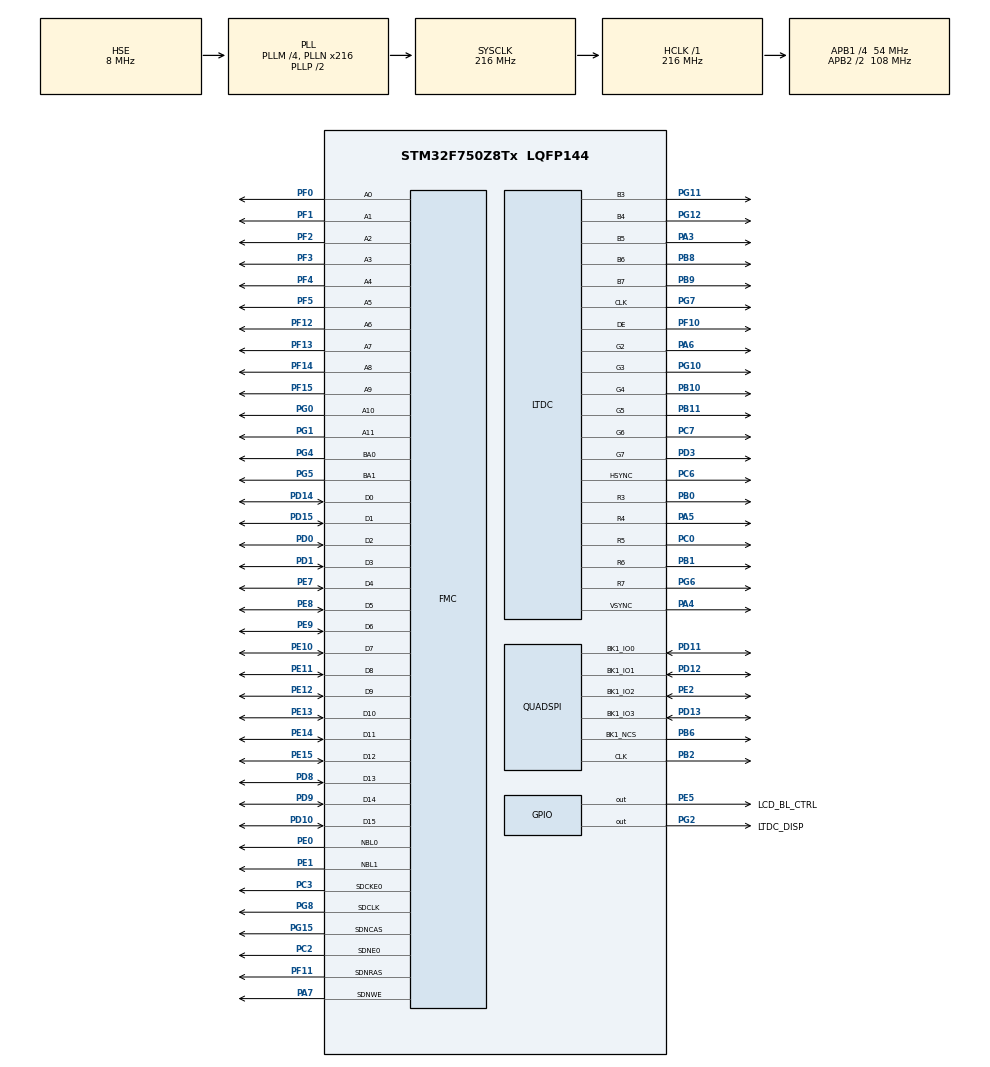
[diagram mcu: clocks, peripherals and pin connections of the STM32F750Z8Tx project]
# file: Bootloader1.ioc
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CORTEX_M7.CPU_DCache=Disabled
CORTEX_M7.CPU_ICache=Disabled
CORTEX_M7.MPU_Control=__NULL
DMA2D.ColorMode=DMA2D_OUTPUT_RGB565
Dma.MEMTOMEM.1.Direction=DMA_MEMORY_TO_MEMORY
Dma.MEMTOMEM.1.FIFOMode=DMA_FIFOMODE_ENABLE
Dma.MEMTOMEM.1.FIFOThreshold=DMA_FIFO_THRESHOLD_FULL
Dma.MEMTOMEM.1.Instance=DMA2_Stream0
Dma.MEMTOMEM.1.MemBurst=DMA_MBURST_SINGLE
Dma.MEMTOMEM.1.MemDataAlignment=DMA_MDATAALIGN_BYTE
Dma.MEMTOMEM.1.MemInc=DMA_MINC_ENABLE
Dma.MEMTOMEM.1.Mode=DMA_NORMAL
Dma.MEMTOMEM.1.PeriphBurst=DMA_PBURST_SINGLE
Dma.MEMTOMEM.1.PeriphDataAlignment=DMA_PDATAALIGN_BYTE
Dma.MEMTOMEM.1.PeriphInc=DMA_PINC_ENABLE
Dma.MEMTOMEM.1.Priority=DMA_PRIORITY_LOW
Dma.QUADSPI.0.Direction=DMA_PERIPH_TO_MEMORY
Dma.QUADSPI.0.FIFOMode=DMA_FIFOMODE_DISABLE
Dma.QUADSPI.0.Instance=DMA2_Stream7
Dma.QUADSPI.0.MemDataAlignment=DMA_MDATAALIGN_BYTE
Dma.QUADSPI.0.MemInc=DMA_MINC_ENABLE
Dma.QUADSPI.0.Mode=DMA_NORMAL
Dma.QUADSPI.0.PeriphDataAlignment=DMA_PDATAALIGN_BYTE
Dma.QUADSPI.0.PeriphInc=DMA_PINC_DISABLE
Dma.QUADSPI.0.Priority=DMA_PRIORITY_LOW
Dma.Request0=QUADSPI
Dma.Request1=MEMTOMEM
FMC.CASLatency1=FMC_SDRAM_CAS_LATENCY_3
FMC.ExitSelfRefreshDelay1=7
FMC.LoadToActiveDelay1=2
FMC.RCDDelay1=2
FMC.RPDelay1=2
FMC.ReadBurst1=FMC_SDRAM_RBURST_ENABLE
FMC.RowCycleDelay1=7
FMC.SDClockPeriod1=FMC_SDRAM_CLOCK_PERIOD_2
FMC.SelfRefreshTime1=4
FMC.WriteRecoveryTime1=3
LTDC.ActiveH=480
LTDC.ActiveW=800
LTDC.Alpha_L0=255
LTDC.FBStartAdress_L0=0xC0500000
LTDC.HBP=8
LTDC.HFP=8
LTDC.HSync=4
LTDC.ImageHeight_L0=480
LTDC.ImageWidth_L0=800
LTDC.Layers=0
LTDC.PCPolarity=LTDC_PCPOLARITY_IPC
LTDC.PixelFormat_L0=LTDC_PIXEL_FORMAT_RGB565
LTDC.VBP=8
LTDC.VFP=8
LTDC.VSync=4
LTDC.WindowX1_L0=800
LTDC.WindowY1_L0=480
Mcu.Family=STM32F7
Mcu.Name=STM32F750Z8Tx
Mcu.Package=LQFP144
NVIC.DMA2_Stream7_IRQn=true\:0\:0\:false\:false\:true\:false\:true
NVIC.FMC_IRQn=true\:0\:0\:false\:false\:true\:true\:true
NVIC.LTDC_ER_IRQn=true\:0\:0\:false\:false\:true\:true\:true
NVIC.LTDC_IRQn=true\:0\:0\:false\:false\:true\:true\:true
NVIC.PriorityGroup=NVIC_PRIORITYGROUP_4
NVIC.TIM2_IRQn=true\:0\:0\:false\:false\:true\:true\:true
NVIC.TIM5_IRQn=true\:0\:0\:false\:false\:true\:false\:true
NVIC.TimeBase=TIM5_IRQn
NVIC.TimeBaseIP=TIM5
PA1.Signal=LTDC_R2
PA13.Mode=Serial_Wire
PA13.Signal=SYS_JTMS-SWDIO
PA14.Mode=Serial_Wire
PA14.Signal=SYS_JTCK-SWCLK
PA3.Mode=RGB565
PA3.Signal=LTDC_B5
PA4.Mode=RGB565
PA4.Signal=LTDC_VSYNC
PA5.Mode=RGB565
PA5.Signal=LTDC_R4
PA6.Mode=RGB565
PA6.Signal=LTDC_G2
PA7.Signal=FMC_SDNWE
PB0.Mode=RGB565
PB0.Signal=LTDC_R3
PB1.Mode=RGB565
PB1.Signal=LTDC_R6
PB10.Mode=RGB565
PB10.Signal=LTDC_G4
PB11.Mode=RGB565
PB11.Signal=LTDC_G5
PB2.Mode=Single Bank 1
PB2.Signal=QUADSPI_CLK
PB3.Signal=SYS_JTDO-SWO
PB6.Mode=Single Bank 1
PB6.Signal=QUADSPI_BK1_NCS
PB8.Mode=RGB565
PB8.Signal=LTDC_B6
PB9.Mode=RGB565
PB9.Signal=LTDC_B7
PC0.Mode=RGB565
PC0.Signal=LTDC_R5
PC2.Mode=SdramChipSelect1_1
PC2.Signal=FMC_SDNE0
PC3.Mode=SdramChipSelect1_1
PC3.Signal=FMC_SDCKE0
PC6.Mode=RGB565
PC6.Signal=LTDC_HSYNC
PC7.Mode=RGB565
PC7.Signal=LTDC_G6
PD0.Signal=FMC_D2_DA2
PD1.Signal=FMC_D3_DA3
PD10.Signal=FMC_D15_DA15
PD11.Mode=Single Bank 1
PD11.Signal=QUADSPI_BK1_IO0
PD12.Mode=Single Bank 1
PD12.Signal=QUADSPI_BK1_IO1
PD13.Mode=Single Bank 1
PD13.Signal=QUADSPI_BK1_IO3
PD14.Signal=FMC_D0_DA0
PD15.Signal=FMC_D1_DA1
PD3.Mode=RGB565
PD3.Signal=LTDC_G7
PD6.Signal=LTDC_B2
PD8.Signal=FMC_D13_DA13
PD9.Signal=FMC_D14_DA14
PE0.Signal=FMC_NBL0
PE1.Signal=FMC_NBL1
PE10.Signal=FMC_D7_DA7
PE11.Signal=FMC_D8_DA8
PE12.Signal=FMC_D9_DA9
PE13.Signal=FMC_D10_DA10
PE14.Signal=FMC_D11_DA11
PE15.Signal=FMC_D12_DA12
PE2.Mode=Single Bank 1
PE2.Signal=QUADSPI_BK1_IO2
PE5.GPIO_Label=LCD_BL_CTRL
PE5.Signal=GPIO_Output
PE7.Signal=FMC_D4_DA4
PE8.Signal=FMC_D5_DA5
PE9.Signal=FMC_D6_DA6
PF0.Signal=FMC_A0
PF1.Signal=FMC_A1
PF10.Mode=RGB565
PF10.Signal=LTDC_DE
PF11.Signal=FMC_SDNRAS
PF12.Signal=FMC_A6
PF13.Signal=FMC_A7
PF14.Signal=FMC_A8
PF15.Signal=FMC_A9
PF2.Signal=FMC_A2
PF3.Signal=FMC_A3
PF4.Signal=FMC_A4
PF5.Signal=FMC_A5
PG0.Signal=FMC_A10
PG1.Signal=FMC_A11
PG10.Mode=RGB565
PG10.Signal=LTDC_G3
PG11.Mode=RGB565
PG11.Signal=LTDC_B3
PG12.Mode=RGB565
PG12.Signal=LTDC_B4
PG15.Signal=FMC_SDNCAS
PG2.GPIO_Label=LTDC_DISP
PG2.Signal=GPIO_Output
PG4.Signal=FMC_A14_BA0
PG5.Signal=FMC_A15_BA1
PG6.Mode=RGB565
PG6.Signal=LTDC_R7
PG7.Mode=RGB565
PG7.Signal=LTDC_CLK
PG8.Signal=FMC_SDCLK
PH0/OSC_IN.Mode=HSE-External-Oscillator
PH0/OSC_IN.Signal=RCC_OSC_IN
PH1/OSC_OUT.Mode=HSE-External-Oscillator
PH1/OSC_OUT.Signal=RCC_OSC_OUT
ProjectManager.HeapSize=0x200
ProjectManager.StackSize=0x400
ProjectManager.TargetToolchain=STM32CubeIDE
QUADSPI.ChipSelectHighTime=QSPI_CS_HIGH_TIME_8_CYCLE
QUADSPI.ClockPrescaler=2
QUADSPI.FifoThreshold=4
QUADSPI.FlashSize=16
QUADSPI.SampleShifting=QSPI_SAMPLE_SHIFTING_NONE
RCC.AHBFreq_Value=216000000
RCC.APB1CLKDivider=RCC_HCLK_DIV4
RCC.APB1Freq_Value=54000000
RCC.APB1TimFreq_Value=108000000
RCC.APB2CLKDivider=RCC_HCLK_DIV2
RCC.APB2Freq_Value=108000000
RCC.APB2TimFreq_Value=216000000
RCC.CortexFreq_Value=216000000
RCC.HCLKFreq_Value=216000000
RCC.HSE_VALUE=8000000
RCC.HSI_VALUE=16000000
RCC.LSE_VALUE=32768
RCC.PLLM=4
RCC.PLLN=216
RCC.PLLSAIN=69
RCC.PLLSAIR=3
RCC.PLLSourceVirtual=RCC_PLLSOURCE_HSE
RCC.SYSCLKFreq_VALUE=216000000
RCC.SYSCLKSource=RCC_SYSCLKSOURCE_PLLCLK
RCC.USBFreq_Value=216000000
RCC.VCOOutputFreq_Value=432000000
SH.FMC_A0.0=FMC_A0,12b-sda1
SH.FMC_A1.0=FMC_A1,12b-sda1
SH.FMC_A10.0=FMC_A10,12b-sda1
SH.FMC_A11.0=FMC_A11,12b-sda1
SH.FMC_A14_BA0.0=FMC_BA0,FourSdramBanks1
SH.FMC_A15_BA1.0=FMC_BA1,FourSdramBanks1
SH.FMC_A2.0=FMC_A2,12b-sda1
SH.FMC_A3.0=FMC_A3,12b-sda1
SH.FMC_A4.0=FMC_A4,12b-sda1
SH.FMC_A5.0=FMC_A5,12b-sda1
SH.FMC_A6.0=FMC_A6,12b-sda1
SH.FMC_A7.0=FMC_A7,12b-sda1
SH.FMC_A8.0=FMC_A8,12b-sda1
SH.FMC_A9.0=FMC_A9,12b-sda1
SH.FMC_D0_DA0.0=FMC_D0,sd-16b-d1
SH.FMC_D10_DA10.0=FMC_D10,sd-16b-d1
SH.FMC_D11_DA11.0=FMC_D11,sd-16b-d1
SH.FMC_D12_DA12.0=FMC_D12,sd-16b-d1
SH.FMC_D13_DA13.0=FMC_D13,sd-16b-d1
SH.FMC_D14_DA14.0=FMC_D14,sd-16b-d1
SH.FMC_D15_DA15.0=FMC_D15,sd-16b-d1
SH.FMC_D1_DA1.0=FMC_D1,sd-16b-d1
SH.FMC_D2_DA2.0=FMC_D2,sd-16b-d1
SH.FMC_D3_DA3.0=FMC_D3,sd-16b-d1
SH.FMC_D4_DA4.0=FMC_D4,sd-16b-d1
SH.FMC_D5_DA5.0=FMC_D5,sd-16b-d1
SH.FMC_D6_DA6.0=FMC_D6,sd-16b-d1
SH.FMC_D7_DA7.0=FMC_D7,sd-16b-d1
SH.FMC_D8_DA8.0=FMC_D8,sd-16b-d1
SH.FMC_D9_DA9.0=FMC_D9,sd-16b-d1
SH.FMC_NBL0.0=FMC_NBL0,Sd2ByteEnable1
SH.FMC_NBL1.0=FMC_NBL1,Sd2ByteEnable1
SH.FMC_SDCLK.0=FMC_SDCLK,12b-sda1
SH.FMC_SDNCAS.0=FMC_SDNCAS,12b-sda1
SH.FMC_SDNRAS.0=FMC_SDNRAS,12b-sda1
SH.FMC_SDNWE.0=FMC_SDNWE,12b-sda1
TIM2.Period=1000-1
TIM2.Prescaler=540-1
TIM7.Period=0
VP_DMA2D_VS_DMA2D.Mode=DMA2D_Activate
VP_SYS_VS_tim5.Mode=TIM5
VP_TIM2_VS_ClockSourceINT.Mode=Internal
VP_TIM7_VS_ClockSourceINT.Mode=Enable_Timer
board=custom

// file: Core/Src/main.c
/* USER CODE BEGIN Header */
/**
 ******************************************************************************
 * @file           : main.c
 * @brief          : Main program body
 ******************************************************************************
 * @attention
 *
 * <h2><center>&copy; Copyright (c) 2020 STMicroelectronics.
 * All rights reserved.</center></h2>
 *
 * This software component is licensed by ST under Ultimate Liberty license
 * SLA0044, the "License"; You may not use this file except in compliance with
 * the License. You may obtain a copy of the License at:
 *                             www.st.com/SLA0044
 *
 ******************************************************************************
 */
/* USER CODE END Header */
#include "main.h"

/* USER CODE BEGIN Includes */
#include "memory.h"
#include "qspi.h"
#include "crc.h"
#include <stdbool.h>
#include <string.h>

/* USER CODE END Includes */

/* USER CODE BEGIN PTD */

typedef struct FileHeader {
  uint32_t crcFile;
  uint32_t fileType;
  uint32_t fileOffset;
  uint32_t dummy3;
  uint32_t dummy4;
  uint32_t dummy5;
  uint32_t fileSize;
  uint32_t crcHeader;
} FileHeader_t;

typedef void (*pFunction)(void);

/* USER CODE END PTD */

/* USER CODE BEGIN PD */
//
#define ADDR_SDRAM_BASE         ((uint32_t)0xC0000000)
#define ADDR_SDRAM_APPLICATION  ((uint32_t)0xC0020000)
#define ADDR_DISPLAY_MEM    ((uint32_t)0xC0500000)

#define APPLICATION_FILEHEAD      0x90020200
#define APPLICATION_BASE          0x90020000

#define COLORBLACK 0x00000000
#define COLORWHITE 0xFFFFFFFF
#define COLORRED   0x78007800
#define COLORBLUE  0x001F001F

/* USER CODE END PD */

DMA2D_HandleTypeDef hdma2d;

LTDC_HandleTypeDef hltdc;

QSPI_HandleTypeDef hqspi;
DMA_HandleTypeDef hdma_quadspi;

TIM_HandleTypeDef htim2;
TIM_HandleTypeDef htim7;

DMA_HandleTypeDef hdma_memtomem_dma2_stream0;
SDRAM_HandleTypeDef hsdram1;

/* USER CODE BEGIN PV */
extern TIM_HandleTypeDef htim5;

uint8_t color = 0x1F;

/* USER CODE END PV */

void SystemClock_Config(void);
static void MX_GPIO_Init(void);
static void MX_DMA_Init(void);
static void MX_QUADSPI_Init(void);
static void MX_DMA2D_Init(void);
static void MX_LTDC_Init(void);
static void MX_FMC_Init(void);
static void MX_TIM7_Init(void);
static void MX_TIM2_Init(void);
/* USER CODE BEGIN PFP */
void MX_SDRAM_InitEx(void);

#ifdef __GNUC__
/* With GCC, small printf (option LD Linker->Libraries->Small printf
   set to 'Yes') calls __io_putchar() */
#define PUTCHAR_PROTOTYPE int __io_putchar(int ch)
#else
#define PUTCHAR_PROTOTYPE int fputc(int ch, FILE *f)
#endif /* __GNUC__ */

/* USER CODE END PFP */

/* USER CODE BEGIN 0 */

void HW_VerifySDRAM(void)
{
  volatile uint32_t *pBuf = (uint32_t*) 0xc0000000;

  static uint32_t failCnt = 0;
  uint32_t cnt = 8 * 1024 * 1024 / 4;

  for (uint32_t i = 0; i < cnt; i++)
    *(pBuf++) = i;

  pBuf = (uint32_t*) 0xc0000000;

  for (uint32_t i = 0; i < cnt; i++)
    if (*(pBuf++) != i)
      failCnt++;
}

void HW_VerifyLCD(void)
{
  uint16_t posX = 0;
  uint16_t posY = 0;

  volatile uint16_t *pFrameBuf = (uint16_t*) ADDR_DISPLAY_MEM;

  for (posY = 0; posY < 480; posY++)
  {
	  *pFrameBuf = color;
    for (posX = 0; posX < 800; posX++)
    {
    	*pFrameBuf = color;
      pFrameBuf++;
    }
  }
}
/**
  * @brief  Retargets the C library printf function to the USART.
  * @param  None
  * @retval None
  */
#if 0
PUTCHAR_PROTOTYPE
{
  /* Place your implementation of fputc here */
  /* e.g. write a character to the EVAL_COM1 and Loop until the end of transmission */
  HAL_UART_Transmit(&huart5, (uint8_t *)&ch, 1, 0xFFFF);

  return ch;
}
#endif

void LCD_Power_On_Sequence()
{
	HAL_GPIO_WritePin(LTDC_DISP_GPIO_Port, LTDC_DISP_Pin, GPIO_PIN_RESET);

	HAL_Delay( 100 );

	HAL_GPIO_WritePin(LTDC_DISP_GPIO_Port, LTDC_DISP_Pin, GPIO_PIN_SET);

	HAL_Delay( 25 );
}

uint8_t CheckApplicationChecksum()
{
  uint32_t crc;

  FileHeader_t *head = ( FileHeader_t* )( APPLICATION_FILEHEAD );

  crc = crc32( 0xDEADBEEF, ( uint8_t* )head, sizeof( FileHeader_t ) - 4 );

  if( crc != head->crcHeader )
    return false;

  uint32_t len = ( APPLICATION_FILEHEAD - APPLICATION_BASE );
  crc = crc32( 0xDEADBEEF, ( uint8_t* )APPLICATION_BASE, len );

  len = head->fileSize - ( APPLICATION_FILEHEAD - APPLICATION_BASE ) - sizeof( FileHeader_t );
  crc = crc32( crc, ( uint8_t* )( APPLICATION_FILEHEAD + sizeof( FileHeader_t ) ), len );

  if( crc != head->crcFile )
    return false;

  return true;
}

static void startApplication()
{
  HAL_LTDC_DeInit(&hltdc);
  HAL_TIM_Base_DeInit(&htim5);
  HAL_TIM_Base_DeInit(&htim7);

  pFunction JumpToRunCode;

  SysTick->CTRL = 0;
  uint32_t appAddress = SDRAM_DEVICE_ADDR_APPLICATION;
  /* Initialize user application's Stack Pointer & Jump to user application */
  JumpToRunCode = (pFunction) (*(__IO uint32_t*) (appAddress + 4));
  __set_MSP(*(__IO uint32_t*) appAddress);

  JumpToRunCode();
}

/* USER CODE END 0 */

int main(void)
{
  /* USER CODE BEGIN 1 */
  MPU_Region_InitTypeDef MPU_InitStruct;

  /* Configure unused area of QSPI region as strongly ordered.
   * This is *important* to avoid unintentional fetches from illegal
   * addresses due to cache/speculation which would halt the MCU.
   */
  HAL_MPU_Disable();

  /* Enable D-cache on SDRAM (Write-through) */
  MPU_InitStruct.Enable = MPU_REGION_ENABLE;
  MPU_InitStruct.BaseAddress = ADDR_SDRAM_BASE;
  MPU_InitStruct.Size = MPU_REGION_SIZE_8MB;
  MPU_InitStruct.AccessPermission = MPU_REGION_FULL_ACCESS;
  MPU_InitStruct.IsBufferable = MPU_ACCESS_NOT_BUFFERABLE;
  MPU_InitStruct.IsCacheable = MPU_ACCESS_CACHEABLE;
  MPU_InitStruct.IsShareable = MPU_ACCESS_NOT_SHAREABLE;
  MPU_InitStruct.Number = MPU_REGION_NUMBER0;
  MPU_InitStruct.TypeExtField = MPU_TEX_LEVEL0;
  MPU_InitStruct.SubRegionDisable = 0x00;
  //MPU_InitStruct.DisableExec = MPU_INSTRUCTION_ACCESS_DISABLE;
  MPU_InitStruct.DisableExec = MPU_INSTRUCTION_ACCESS_ENABLE;

  HAL_MPU_ConfigRegion(&MPU_InitStruct);

  HAL_MPU_Enable(MPU_PRIVILEGED_DEFAULT);
  /* USER CODE END 1 */

  /* MCU Configuration--------------------------------------------------------*/

  /* Reset of all peripherals, Initializes the Flash interface and the Systick. */
  HAL_Init();

  /* Configure the system clock */
  SystemClock_Config();

  /* Initialize all configured peripherals */
  MX_GPIO_Init();
  MX_DMA_Init();
  MX_QUADSPI_Init();
  MX_DMA2D_Init();
  MX_LTDC_Init();
  MX_FMC_Init();
  MX_TIM7_Init();
  MX_TIM2_Init();
  /* USER CODE BEGIN 2 */
  BSP_QSPI_Init(&hqspi);
  BSP_QSPI_EnableMemoryMappedMode(&hqspi);
  //   HW_VerifySDRAM()

   // Enable Backlight
   LCD_Power_On_Sequence();
   memset( (void *)( ADDR_DISPLAY_MEM ), 0x00, ( 800 * 480 * 2 ) );
   memcpy( (void*)ADDR_SDRAM_APPLICATION, (void*)APPLICATION_BASE, 1024*1024-128*1024-64 );
   startApplication();
  /* USER CODE END 2 */

  /* Infinite loop */
  while (1) {

  }
}

void SystemClock_Config(void)
{
  RCC_OscInitTypeDef RCC_OscInitStruct = {0};
  RCC_ClkInitTypeDef RCC_ClkInitStruct = {0};
  RCC_PeriphCLKInitTypeDef PeriphClkInitStruct = {0};

  /** Configure the main internal regulator output voltage
  */
  __HAL_RCC_PWR_CLK_ENABLE();
  __HAL_PWR_VOLTAGESCALING_CONFIG(PWR_REGULATOR_VOLTAGE_SCALE1);
  /** Initializes the RCC Oscillators according to the specified parameters
  * in the RCC_OscInitTypeDef structure.
  */
  RCC_OscInitStruct.OscillatorType = RCC_OSCILLATORTYPE_HSE;
  RCC_OscInitStruct.HSEState = RCC_HSE_ON;
  RCC_OscInitStruct.PLL.PLLState = RCC_PLL_ON;
  RCC_OscInitStruct.PLL.PLLSource = RCC_PLLSOURCE_HSE;
  RCC_OscInitStruct.PLL.PLLM = 4;
  RCC_OscInitStruct.PLL.PLLN = 216;
  RCC_OscInitStruct.PLL.PLLP = RCC_PLLP_DIV2;
  RCC_OscInitStruct.PLL.PLLQ = 2;
  if (HAL_RCC_OscConfig(&RCC_OscInitStruct) != HAL_OK)
  {
    Error_Handler();
  }
  /** Activate the Over-Drive mode
  */
  if (HAL_PWREx_EnableOverDrive() != HAL_OK)
  {
    Error_Handler();
  }
  /** Initializes the CPU, AHB and APB buses clocks
  */
  RCC_ClkInitStruct.ClockType = RCC_CLOCKTYPE_HCLK|RCC_CLOCKTYPE_SYSCLK
                              |RCC_CLOCKTYPE_PCLK1|RCC_CLOCKTYPE_PCLK2;
  RCC_ClkInitStruct.SYSCLKSource = RCC_SYSCLKSOURCE_PLLCLK;
  RCC_ClkInitStruct.AHBCLKDivider = RCC_SYSCLK_DIV1;
  RCC_ClkInitStruct.APB1CLKDivider = RCC_HCLK_DIV4;
  RCC_ClkInitStruct.APB2CLKDivider = RCC_HCLK_DIV2;

  if (HAL_RCC_ClockConfig(&RCC_ClkInitStruct, FLASH_LATENCY_7) != HAL_OK)
  {
    Error_Handler();
  }
  PeriphClkInitStruct.PeriphClockSelection = RCC_PERIPHCLK_LTDC;
  PeriphClkInitStruct.PLLSAI.PLLSAIN = 69;
  PeriphClkInitStruct.PLLSAI.PLLSAIR = 3;
  PeriphClkInitStruct.PLLSAI.PLLSAIQ = 2;
  PeriphClkInitStruct.PLLSAI.PLLSAIP = RCC_PLLSAIP_DIV2;
  PeriphClkInitStruct.PLLSAIDivQ = 1;
  PeriphClkInitStruct.PLLSAIDivR = RCC_PLLSAIDIVR_2;
  if (HAL_RCCEx_PeriphCLKConfig(&PeriphClkInitStruct) != HAL_OK)
  {
    Error_Handler();
  }
}

static void MX_DMA2D_Init(void)
{

  hdma2d.Instance = DMA2D;
  hdma2d.Init.Mode = DMA2D_M2M;
  hdma2d.Init.ColorMode = DMA2D_OUTPUT_RGB565;
  hdma2d.Init.OutputOffset = 0;
  hdma2d.LayerCfg[1].InputOffset = 0;
  hdma2d.LayerCfg[1].InputColorMode = DMA2D_INPUT_RGB565;
  hdma2d.LayerCfg[1].AlphaMode = DMA2D_NO_MODIF_ALPHA;
  hdma2d.LayerCfg[1].InputAlpha = 0;
  if (HAL_DMA2D_Init(&hdma2d) != HAL_OK)
  {
    Error_Handler();
  }
  if (HAL_DMA2D_ConfigLayer(&hdma2d, 1) != HAL_OK)
  {
    Error_Handler();
  }

}

static void MX_LTDC_Init(void)
{

  LTDC_LayerCfgTypeDef pLayerCfg = {0};
  LTDC_LayerCfgTypeDef pLayerCfg1 = {0};

  hltdc.Instance = LTDC;
  hltdc.Init.HSPolarity = LTDC_HSPOLARITY_AL;
  hltdc.Init.VSPolarity = LTDC_VSPOLARITY_AL;
  hltdc.Init.DEPolarity = LTDC_DEPOLARITY_AL;
  hltdc.Init.PCPolarity = LTDC_PCPOLARITY_IPC;
  hltdc.Init.HorizontalSync = 3;
  hltdc.Init.VerticalSync = 3;
  hltdc.Init.AccumulatedHBP = 11;
  hltdc.Init.AccumulatedVBP = 11;
  hltdc.Init.AccumulatedActiveW = 811;
  hltdc.Init.AccumulatedActiveH = 491;
  hltdc.Init.TotalWidth = 819;
  hltdc.Init.TotalHeigh = 499;
  hltdc.Init.Backcolor.Blue = 0;
  hltdc.Init.Backcolor.Green = 0;
  hltdc.Init.Backcolor.Red = 0;
  if (HAL_LTDC_Init(&hltdc) != HAL_OK)
  {
    Error_Handler();
  }
  pLayerCfg.WindowX0 = 0;
  pLayerCfg.WindowX1 = 800;
  pLayerCfg.WindowY0 = 0;
  pLayerCfg.WindowY1 = 480;
  pLayerCfg.PixelFormat = LTDC_PIXEL_FORMAT_RGB565;
  pLayerCfg.Alpha = 255;
  pLayerCfg.Alpha0 = 0;
  pLayerCfg.BlendingFactor1 = LTDC_BLENDING_FACTOR1_CA;
  pLayerCfg.BlendingFactor2 = LTDC_BLENDING_FACTOR2_CA;
  pLayerCfg.FBStartAdress = 0xC0500000;
  pLayerCfg.ImageWidth = 800;
  pLayerCfg.ImageHeight = 480;
  pLayerCfg.Backcolor.Blue = 0;
  pLayerCfg.Backcolor.Green = 0;
  pLayerCfg.Backcolor.Red = 0;
  if (HAL_LTDC_ConfigLayer(&hltdc, &pLayerCfg, 0) != HAL_OK)
  {
    Error_Handler();
  }
  pLayerCfg1.WindowX0 = 0;
  pLayerCfg1.WindowX1 = 0;
  pLayerCfg1.WindowY0 = 0;
  pLayerCfg1.WindowY1 = 0;
  pLayerCfg1.Alpha = 0;
  pLayerCfg1.Alpha0 = 0;
  pLayerCfg1.BlendingFactor1 = LTDC_BLENDING_FACTOR1_CA;
  pLayerCfg1.BlendingFactor2 = LTDC_BLENDING_FACTOR2_CA;
  pLayerCfg1.FBStartAdress = 0;
  pLayerCfg1.ImageWidth = 0;
  pLayerCfg1.ImageHeight = 0;
  pLayerCfg1.Backcolor.Blue = 0;
  pLayerCfg1.Backcolor.Green = 0;
  pLayerCfg1.Backcolor.Red = 0;
  if (HAL_LTDC_ConfigLayer(&hltdc, &pLayerCfg1, 1) != HAL_OK)
  {
    Error_Handler();
  }

}

static void MX_QUADSPI_Init(void)
{

  /* QUADSPI parameter configuration*/
  hqspi.Instance = QUADSPI;
  hqspi.Init.ClockPrescaler = 2;
  hqspi.Init.FifoThreshold = 4;
  hqspi.Init.SampleShifting = QSPI_SAMPLE_SHIFTING_NONE;
  hqspi.Init.FlashSize = 16;
  hqspi.Init.ChipSelectHighTime = QSPI_CS_HIGH_TIME_8_CYCLE;
  hqspi.Init.ClockMode = QSPI_CLOCK_MODE_0;
  hqspi.Init.FlashID = QSPI_FLASH_ID_1;
  hqspi.Init.DualFlash = QSPI_DUALFLASH_DISABLE;
  if (HAL_QSPI_Init(&hqspi) != HAL_OK)
  {
    Error_Handler();
  }

}

static void MX_TIM2_Init(void)
{

  TIM_ClockConfigTypeDef sClockSourceConfig = {0};
  TIM_MasterConfigTypeDef sMasterConfig = {0};

  htim2.Instance = TIM2;
  htim2.Init.Prescaler = 540-1;
  htim2.Init.CounterMode = TIM_COUNTERMODE_UP;
  htim2.Init.Period = 1000-1;
  htim2.Init.ClockDivision = TIM_CLOCKDIVISION_DIV1;
  htim2.Init.AutoReloadPreload = TIM_AUTORELOAD_PRELOAD_DISABLE;
  if (HAL_TIM_Base_Init(&htim2) != HAL_OK)
  {
    Error_Handler();
  }
  sClockSourceConfig.ClockSource = TIM_CLOCKSOURCE_INTERNAL;
  if (HAL_TIM_ConfigClockSource(&htim2, &sClockSourceConfig) != HAL_OK)
  {
    Error_Handler();
  }
  sMasterConfig.MasterOutputTrigger = TIM_TRGO_RESET;
  sMasterConfig.MasterSlaveMode = TIM_MASTERSLAVEMODE_DISABLE;
  if (HAL_TIMEx_MasterConfigSynchronization(&htim2, &sMasterConfig) != HAL_OK)
  {
    Error_Handler();
  }

}

static void MX_TIM7_Init(void)
{

  TIM_MasterConfigTypeDef sMasterConfig = {0};

  htim7.Instance = TIM7;
  htim7.Init.Prescaler = 0;
  htim7.Init.CounterMode = TIM_COUNTERMODE_UP;
  htim7.Init.Period = 0;
  htim7.Init.AutoReloadPreload = TIM_AUTORELOAD_PRELOAD_DISABLE;
  if (HAL_TIM_Base_Init(&htim7) != HAL_OK)
  {
    Error_Handler();
  }
  sMasterConfig.MasterOutputTrigger = TIM_TRGO_RESET;
  sMasterConfig.MasterSlaveMode = TIM_MASTERSLAVEMODE_DISABLE;
  if (HAL_TIMEx_MasterConfigSynchronization(&htim7, &sMasterConfig) != HAL_OK)
  {
    Error_Handler();
  }

}

static void MX_DMA_Init(void)
{

  /* DMA controller clock enable */
  __HAL_RCC_DMA2_CLK_ENABLE();

  /* Configure DMA request hdma_memtomem_dma2_stream0 on DMA2_Stream0 */
  hdma_memtomem_dma2_stream0.Instance = DMA2_Stream0;
  hdma_memtomem_dma2_stream0.Init.Channel = DMA_CHANNEL_0;
  hdma_memtomem_dma2_stream0.Init.Direction = DMA_MEMORY_TO_MEMORY;
  hdma_memtomem_dma2_stream0.Init.PeriphInc = DMA_PINC_ENABLE;
  hdma_memtomem_dma2_stream0.Init.MemInc = DMA_MINC_ENABLE;
  hdma_memtomem_dma2_stream0.Init.PeriphDataAlignment = DMA_PDATAALIGN_BYTE;
  hdma_memtomem_dma2_stream0.Init.MemDataAlignment = DMA_MDATAALIGN_BYTE;
  hdma_memtomem_dma2_stream0.Init.Mode = DMA_NORMAL;
  hdma_memtomem_dma2_stream0.Init.Priority = DMA_PRIORITY_LOW;
  hdma_memtomem_dma2_stream0.Init.FIFOMode = DMA_FIFOMODE_ENABLE;
  hdma_memtomem_dma2_stream0.Init.FIFOThreshold = DMA_FIFO_THRESHOLD_FULL;
  hdma_memtomem_dma2_stream0.Init.MemBurst = DMA_MBURST_SINGLE;
  hdma_memtomem_dma2_stream0.Init.PeriphBurst = DMA_PBURST_SINGLE;
  if (HAL_DMA_Init(&hdma_memtomem_dma2_stream0) != HAL_OK)
  {
    Error_Handler( );
  }

  /* DMA interrupt init */
  /* DMA2_Stream7_IRQn interrupt configuration */
  HAL_NVIC_SetPriority(DMA2_Stream7_IRQn, 0, 0);
  HAL_NVIC_EnableIRQ(DMA2_Stream7_IRQn);

}

/* FMC initialization function */
static void MX_FMC_Init(void)
{

  FMC_SDRAM_TimingTypeDef SdramTiming = {0};

  /** Perform the SDRAM1 memory initialization sequence
  */
  hsdram1.Instance = FMC_SDRAM_DEVICE;
  /* hsdram1.Init */
  hsdram1.Init.SDBank = FMC_SDRAM_BANK1;
  hsdram1.Init.ColumnBitsNumber = FMC_SDRAM_COLUMN_BITS_NUM_8;
  hsdram1.Init.RowBitsNumber = FMC_SDRAM_ROW_BITS_NUM_12;
  hsdram1.Init.MemoryDataWidth = FMC_SDRAM_MEM_BUS_WIDTH_16;
  hsdram1.Init.InternalBankNumber = FMC_SDRAM_INTERN_BANKS_NUM_4;
  hsdram1.Init.CASLatency = FMC_SDRAM_CAS_LATENCY_3;
  hsdram1.Init.WriteProtection = FMC_SDRAM_WRITE_PROTECTION_DISABLE;
  hsdram1.Init.SDClockPeriod = FMC_SDRAM_CLOCK_PERIOD_2;
  hsdram1.Init.ReadBurst = FMC_SDRAM_RBURST_ENABLE;
  hsdram1.Init.ReadPipeDelay = FMC_SDRAM_RPIPE_DELAY_0;
  /* SdramTiming */
  SdramTiming.LoadToActiveDelay = 2;
  SdramTiming.ExitSelfRefreshDelay = 7;
  SdramTiming.SelfRefreshTime = 4;
  SdramTiming.RowCycleDelay = 7;
  SdramTiming.WriteRecoveryTime = 3;
  SdramTiming.RPDelay = 2;
  SdramTiming.RCDDelay = 2;

  if (HAL_SDRAM_Init(&hsdram1, &SdramTiming) != HAL_OK)
  {
    Error_Handler( );
  }

  /* USER CODE BEGIN FMC_Init 2 */
  MX_SDRAM_InitEx();
  /* USER CODE END FMC_Init 2 */
}

static void MX_GPIO_Init(void)
{
  GPIO_InitTypeDef GPIO_InitStruct = {0};

  /* GPIO Ports Clock Enable */
  __HAL_RCC_GPIOE_CLK_ENABLE();
  __HAL_RCC_GPIOF_CLK_ENABLE();
  __HAL_RCC_GPIOH_CLK_ENABLE();
  __HAL_RCC_GPIOC_CLK_ENABLE();
  __HAL_RCC_GPIOA_CLK_ENABLE();
  __HAL_RCC_GPIOB_CLK_ENABLE();
  __HAL_RCC_GPIOG_CLK_ENABLE();
  __HAL_RCC_GPIOD_CLK_ENABLE();

  /*Configure GPIO pin Output Level */
  HAL_GPIO_WritePin(LCD_BL_CTRL_GPIO_Port, LCD_BL_CTRL_Pin, GPIO_PIN_RESET);

  /*Configure GPIO pin Output Level */
  HAL_GPIO_WritePin(LTDC_DISP_GPIO_Port, LTDC_DISP_Pin, GPIO_PIN_RESET);

  /*Configure GPIO pin : LCD_BL_CTRL_Pin */
  GPIO_InitStruct.Pin = LCD_BL_CTRL_Pin;
  GPIO_InitStruct.Mode = GPIO_MODE_OUTPUT_PP;
  GPIO_InitStruct.Pull = GPIO_NOPULL;
  GPIO_InitStruct.Speed = GPIO_SPEED_FREQ_LOW;
  HAL_GPIO_Init(LCD_BL_CTRL_GPIO_Port, &GPIO_InitStruct);

  /*Configure GPIO pin : LTDC_DISP_Pin */
  GPIO_InitStruct.Pin = LTDC_DISP_Pin;
  GPIO_InitStruct.Mode = GPIO_MODE_OUTPUT_PP;
  GPIO_InitStruct.Pull = GPIO_NOPULL;
  GPIO_InitStruct.Speed = GPIO_SPEED_FREQ_LOW;
  HAL_GPIO_Init(LTDC_DISP_GPIO_Port, &GPIO_InitStruct);

}

/* USER CODE BEGIN 4 */
/**
 * @brief  Programs the SDRAM device.
 * @retval None
 */
void MX_SDRAM_InitEx(void)
{

  /* For SDRAM initial */
#define REFRESH_COUNT        1386                                     /*Todo check SDRAM clock*/
#define SDRAM_TIMEOUT                            ((uint32_t)0xFFFF)
#define SDRAM_MODEREG_BURST_LENGTH_1             ((uint16_t)0x0000)
#define SDRAM_MODEREG_BURST_LENGTH_2             ((uint16_t)0x0001)
#define SDRAM_MODEREG_BURST_LENGTH_4             ((uint16_t)0x0002)
#define SDRAM_MODEREG_BURST_LENGTH_8             ((uint16_t)0x0004)
#define SDRAM_MODEREG_BURST_TYPE_SEQUENTIAL      ((uint16_t)0x0000)
#define SDRAM_MODEREG_BURST_TYPE_INTERLEAVED     ((uint16_t)0x0008)
#define SDRAM_MODEREG_CAS_LATENCY_2              ((uint16_t)0x0020)
#define SDRAM_MODEREG_CAS_LATENCY_3              ((uint16_t)0x0030)
#define SDRAM_MODEREG_OPERATING_MODE_STANDARD    ((uint16_t)0x0000)
#define SDRAM_MODEREG_WRITEBURST_MODE_PROGRAMMED ((uint16_t)0x0000)
#define SDRAM_MODEREG_WRITEBURST_MODE_SINGLE     ((uint16_t)0x0200)

  __IO uint32_t tmpmrd = 0;
  FMC_SDRAM_CommandTypeDef Command;

  /* Step 1: Configure a clock configuration enable command */
  Command.CommandMode = FMC_SDRAM_CMD_CLK_ENABLE;
  Command.CommandTarget = FMC_SDRAM_CMD_TARGET_BANK1;
  Command.AutoRefreshNumber = 1;
  Command.ModeRegisterDefinition = 0;

  /* Send the command */
  HAL_SDRAM_SendCommand(&hsdram1, &Command, SDRAM_TIMEOUT);

  /* Step 2: Insert 100 us minimum delay */
  /* Inserted delay is equal to 1 ms due to systick time base unit (ms) */
  HAL_Delay(1);

  /* Step 3: Configure a PALL (precharge all) command */
  Command.CommandMode = FMC_SDRAM_CMD_PALL;
  Command.CommandTarget = FMC_SDRAM_CMD_TARGET_BANK1;
  Command.AutoRefreshNumber = 1;
  Command.ModeRegisterDefinition = 0;

  /* Send the command */
  HAL_SDRAM_SendCommand(&hsdram1, &Command, SDRAM_TIMEOUT);

  /* Step 4: Configure an Auto Refresh command */
  Command.CommandMode = FMC_SDRAM_CMD_AUTOREFRESH_MODE;
  Command.CommandTarget = FMC_SDRAM_CMD_TARGET_BANK1;
  Command.AutoRefreshNumber = 8;
  Command.ModeRegisterDefinition = 0;

  /* Send the command */
  HAL_SDRAM_SendCommand(&hsdram1, &Command, SDRAM_TIMEOUT);

  /* Step 5: Program the external memory mode register */
  /*Todo Check CAS_LATENCY value*/

  tmpmrd = (uint32_t) SDRAM_MODEREG_BURST_LENGTH_1
      |\
 SDRAM_MODEREG_BURST_TYPE_SEQUENTIAL |\
 SDRAM_MODEREG_CAS_LATENCY_3
      |\
 SDRAM_MODEREG_OPERATING_MODE_STANDARD
      |\
 SDRAM_MODEREG_WRITEBURST_MODE_SINGLE;

  Command.CommandMode = FMC_SDRAM_CMD_LOAD_MODE;
  Command.CommandTarget = FMC_SDRAM_CMD_TARGET_BANK1;
  Command.AutoRefreshNumber = 1;
  Command.ModeRegisterDefinition = tmpmrd;

  /* Send the command */
  HAL_SDRAM_SendCommand(&hsdram1, &Command, SDRAM_TIMEOUT);

  /* Step 6: Set the refresh rate counter */
  /* Set the device refresh rate */
  HAL_SDRAM_ProgramRefreshRate(&hsdram1, REFRESH_COUNT);
}
/* USER CODE END 4 */

void HAL_TIM_PeriodElapsedCallback(TIM_HandleTypeDef *htim)
{
  if (htim->Instance == TIM5) {
    HAL_IncTick();
  }
}

void Error_Handler(void)
{
}

/************************ (C) COPYRIGHT STMicroelectronics *****END OF FILE****/
